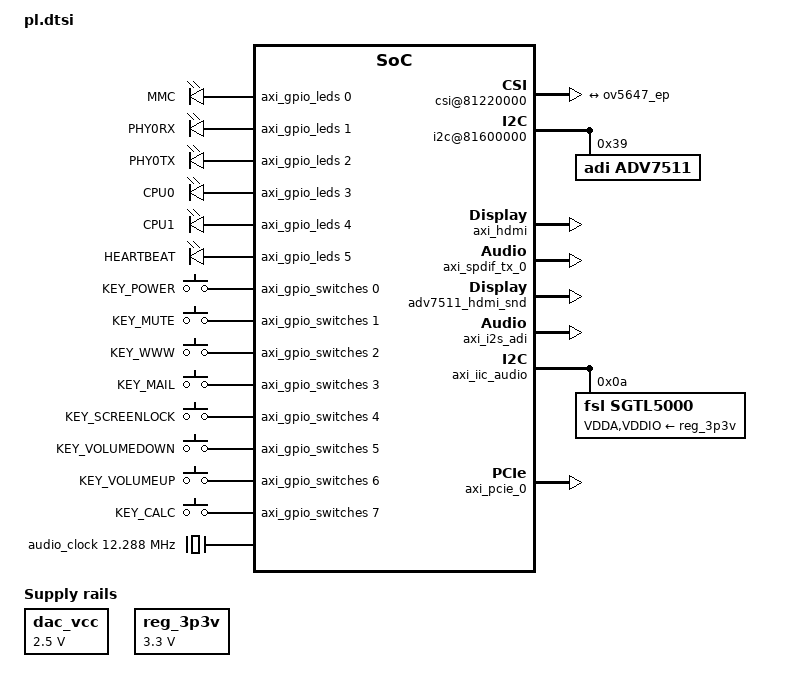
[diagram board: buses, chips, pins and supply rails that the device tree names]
/*
 * CAUTION: This file is automatically generated by Xilinx.
 * Version:  
 * Today is: Wed Jul 22 14:53:28 2015
*/


/ {

	dac_vcc: fixedregulator@1 {
		compatible = "regulator-fixed";
		regulator-name = "fixed-supply";
		regulator-min-microvolt = <2500000>;
		regulator-max-microvolt = <2500000>;
		regulator-boot-on;
	};

	amba_pl: amba_pl {
		#address-cells = <1>;
		#size-cells = <1>;
		compatible = "simple-bus";
		ranges;		
		
		axi_gpio_leds: gpio@81210000 {
			compatible = "xlnx,xps-gpio-1.00.a";
			reg = <0x81210000 0x10000>;
			
			interrupt-parent = <&intc>;
			interrupts = <0 33 4>;	
			
			gpio-controller;
			#gpio-cells = <2>;
			
			xlnx,all-inputs = <0x0>;
			xlnx,all-inputs-2 = <0x0>;
			xlnx,all-outputs = <0x1>;
			xlnx,all-outputs-2 = <0x0>;
			xlnx,dout-default = <0x00000000>;
			xlnx,dout-default-2 = <0x00000000>;
			xlnx,gpio-width = <0x9>;			
			xlnx,gpio2-width = <0x20>;
			xlnx,interrupt-present = <0x1>;
			xlnx,is-dual = <0x0>;
			xlnx,tri-default = <0xFFFFFFFF>;
			xlnx,tri-default-2 = <0xFFFFFFFF>;
		};
		
		axi_gpio_switches: gpio@81200000 {
			compatible = "xlnx,xps-gpio-1.00.a";
			reg = <0x81200000 0x10000>;
			
			interrupt-parent = <&intc>;
			interrupts = <0 34 4>;			
			
			gpio-controller;
			#gpio-cells = <2>;
			
			interrupt-controller;
			#interrupt-cells = <2>;
			
			xlnx,all-inputs = <0x1>;
			xlnx,all-inputs-2 = <0x0>;
			xlnx,all-outputs = <0x0>;
			xlnx,all-outputs-2 = <0x0>;
			xlnx,dout-default = <0x00000000>;
			xlnx,dout-default-2 = <0x00000000>;
			xlnx,gpio-width = <0x9>;
			xlnx,gpio2-width = <0x20>;
			xlnx,interrupt-present = <0x1>;
			xlnx,is-dual = <0x0>;
			xlnx,tri-default = <0xFFFFFFFF>;
			xlnx,tri-default-2 = <0xFFFFFFFF>;
		};		
		
		leds {
			compatible = "gpio-leds";
			
			led0 {
				label = "MMC";
				gpios = <&axi_gpio_leds 0 0>;
				linux,default-trigger = "mmc0";
			};

			led1 {
				label = "PHY0RX";
				gpios = <&axi_gpio_leds 1 0>;
				linux,default-trigger = "phy0rx";
			};

			led2 {
				label = "PHY0TX";
				gpios = <&axi_gpio_leds 2 0>;
				linux,default-trigger = "phy0tx";
			};
			
			led3 {
				label = "CPU0";
				gpios = <&axi_gpio_leds 3 0>;
				linux,default-trigger = "cpu0";
			};

			led4 {
				label = "CPU1";
				gpios = <&axi_gpio_leds 4 0>;
				linux,default-trigger = "cpu1";
			};
			
			led5 {
				label = "HEARTBEAT";
				gpios = <&axi_gpio_leds 5 0>;
				linux,default-trigger = "heartbeat";
			};						
		};
		
		gpio_keys_polled {
			compatible = "gpio-keys-polled";
			#address-cells = <1>;
			#size-cells = <0>;
			poll-interval = <100>;			
			
			switch0 {
				label = "KEY_POWER";
				linux,code = <116>;
				gpios = <&axi_gpio_switches 0 0>;
			};
			
			switch1 {
				label = "KEY_MUTE";
				linux,code = <113>;
				gpios = <&axi_gpio_switches 1 0>;
			};
			
			switch2 {
				label = "KEY_WWW";
				linux,code = <150>;
				gpios = <&axi_gpio_switches 2 0>;
			};
			
			switch3 {
				label = "KEY_MAIL";
				linux,code = <155>;
				gpios = <&axi_gpio_switches 3 0>;
			};
			
			switch4 {
				label = "KEY_SCREENLOCK";
				linux,code = <152>;
				gpios = <&axi_gpio_switches 4 0>;
			};
			
			switch5 {
				label = "KEY_VOLUMEDOWN";
				linux,code = <114>;
				gpios = <&axi_gpio_switches 5 0>;
			};
			
			switch6 {
				label = "KEY_VOLUMEUP";
				linux,code = <115>;
				gpios = <&axi_gpio_switches 6 0>;
			};
			
			switch7 {
				label = "KEY_CALC";
				linux,code = <140>;
				gpios = <&axi_gpio_switches 7 0>;
			};
		};				
		
		csi@81220000 {
			compatible = "s47,axi-csi-rx-1.00.a";
			reg = <0x81220000 0x10000>;

			interrupts = <0 53 4>;
			interrupt-parent = <&intc>;

			dmas = <&axi_camera_vdma 1>;
			dma-names = "video";

			led-gpios = <&axi_gpio_leds 7 0>;

			port {
				csi_ep: endpoint {
					remote-endpoint = <&ov5647_ep>;
					clock-lanes = <0>;
					data-lanes = <1 2>;
				};
			};
		};		
		
		axi_camera_vdma: dma@83010000 {		  
		  
			compatible = "xlnx,axi-vdma-1.00.a";
			#dma-cells = <1>;
			reg = <0x83010000 0x10000>;			
			
			/* Flush both channels on fsync */
			xlnx,flush-fsync = <0x1>;
			/* Number of framebuffers */
			xlnx,num-fstores = <0x4>;	
			
			/* Write channel: camera input */
			dma-channel@83010030 {
				compatible = "xlnx,axi-vdma-s2mm-channel";
				interrupt-parent = <&intc>;
				interrupts = <0 52 4>;
				xlnx,datawidth = <0x40>;
				xlnx,include-dre = <0x0>;				
				xlnx,genlock-mode = <0x0>;
			};
		};	
		
		i2c@81600000 {
			compatible = "xlnx,axi-iic-1.01.b", "xlnx,xps-iic-2.00.a";
			interrupt-parent = <&intc>;
			interrupts = <0 58 0x4>;
			reg = <0x81600000 0x10000>;

			#size-cells = <0>;
			#address-cells = <1>;

			adv7511: adv7511@39 {
				compatible = "adi,adv7511";
				reg = <0x39>;

				adi,input-style = <0x02>;
				adi,input-id = <0x01>;
				adi,input-color-depth = <0x3>;
				adi,sync-pulse = <0x03>;
				adi,bit-justification = <0x01>;
				adi,up-conversion = <0x00>;
				adi,timing-generation-sequence = <0x00>;
				adi,vsync-polarity = <0x02>;
				adi,hsync-polarity = <0x02>;
				adi,tdms-clock-inversion;
				adi,clock-delay = <0x03>;
			};			
		};

		axi_vdma_0: axivdma@83000000 {
			compatible = "xlnx,axi-vdma";
			#address-cells = <1>;
			#size-cells = <1>;
			#dma-cells = <1>;
			#dma-channels = <1>;
			reg = <0x83000000 0x10000>;
			xlnx,include-sg = <0x0>;
			xlnx,num-fstores = <0x3>;
			dma-channel@83000000 {
				compatible = "xlnx,axi-vdma-mm2s-channel";
				interrupt-parent = <&intc>;
				interrupts = <0 59 0x4>;
				xlnx,datawidth = <0x40>;
				xlnx,genlock-mode = <0x0>;
				xlnx,include-dre = <0x0>;
			};
		};

		hdmi_clock: axi-clkgen@83c00000 {
			compatible = "adi,axi-clkgen-2.00.a";
			reg = <0x83c00000 0x10000>;
			#clock-cells = <0>;
			clocks = <&clkc 16>;
		};

		axi_hdmi: axi-hdmi@83c10000 {
			compatible = "adi,axi-hdmi-tx-1.00.a";
			reg = <0x83c10000 0x10000>;
			encoder-slave = <&adv7511>;
			dmas = <&axi_vdma_0 0>;
			dma-names = "video";
			clocks = <&hdmi_clock>;
		};				

		axi_spdif_tx_0: axi-spdif-tx@0x83c20000 {
			compatible = "adi,axi-spdif-tx-1.00.a";
			reg = <0x83c20000 0x10000>;
			dmas = <&dmac_s 0>;
			dma-names = "tx";
			clocks = <&clkc 15>, <&audio_clock>, <&audio_clock>;
			clock-names = "axi", "ref", "spdif";
		};

		adv7511_hdmi_snd: adv7511_hdmi_snd {
			compatible = "adv7511-hdmi-snd";
			audio-codec = <&adv7511>;
			cpu-dai = <&axi_spdif_tx_0>;
		};			
		
		regulators {
			compatible = "simple-bus";			

			reg_3p3v: 3p3v {
				compatible = "regulator-fixed";
				regulator-name = "3P3V";
				regulator-min-microvolt = <3300000>;
				regulator-max-microvolt = <3300000>;
				regulator-always-on;
			};
		};		
		
		axi_i2s_adi: axi_i2s_adi@81640000 {
			#sound-dai-cells = <0>;
			compatible = "adi,axi-i2s-1.00.a";
			reg = <0x81640000 0x10000>;						
			dmas = <&dmac_s 1 &dmac_s 2>;
			dma-names = "tx", "rx";
			clocks = <&clkc 15>, <&audio_clock>;
			clock-names = "axi", "ref";						
		};
		
		axi_iic_audio: i2c@81610000 {
			#address-cells = <1>;
			#size-cells = <0>;
			compatible = "xlnx,axi-iic-1.01.b", "xlnx,xps-iic-2.00.a";
			interrupt-parent = <&intc>;
			interrupts = <0 56 4>;
			reg = <0x81610000 0x10000>;			
			
			sgtl5000: sgtl5000@0a {
				#sound-dai-cells = <0>;
				compatible = "fsl,sgtl5000";
				reg = <0x0a>;
				clocks = <&audio_clock>;								
				VDDA-supply = <&reg_3p3v>;
				VDDIO-supply = <&reg_3p3v>;				
			};			
		};
		
		upc_sgtl_sound {
		  
		    compatible = "simple-audio-card";
		    simple-audio-card,name = "Aldec-uPC-sound";
		    simple-audio-card,format = "i2s";
		    simple-audio-card,bitclock-master = <&dailink0_master>;
		    simple-audio-card,frame-master = <&dailink0_master>;
		    simple-audio-card,mclk-fs = <256>;
		    
		    simple-audio-card,widgets =
			    "Line", "Line In Jack",
			    "Headphone", "Headphone Jack";			    
		    simple-audio-card,routing =
			    "LINE_IN", "Line In Jack",
			    "Headphone Jack", "HP_OUT";		    
		    
		    dailink0_master: simple-audio-card,cpu {
			    sound-dai = <&axi_i2s_adi>;
			    system-clock-frequency = <12288000>;
		    };

		    simple-audio-card,codec {
			    sound-dai = <&sgtl5000>;
			    system-clock-frequency = <12288000>;
		    };		    
		};
		
		axi_pcie_0: axi-pcie@50000000 {
			#address-cells = <3>;
			#interrupt-cells = <1>;
			#size-cells = <2>;
			compatible = "xlnx,axi-pcie-host-1.00.a";
			device_type = "pci";
			interrupt-map = <0 0 0 1 &pcie_intc 1>,
					<0 0 0 2 &pcie_intc 2>,
					<0 0 0 3 &pcie_intc 3>, 
					<0 0 0 4 &pcie_intc 4>;
			interrupt-map-mask = <0 0 0 7>;
			interrupt-parent = <&intc>;
			interrupts = <0 57 4>;
			ranges = <0x02000000 0x00000000 0x60000000 0x60000000 0x00000000 0x10000000>;
			reg = <0x50000000 0x4000000>;
			pcie_intc: interrupt-controller {
				#address-cells = <0>;
				#interrupt-cells = <1>;
				interrupt-controller ;
			};
		};

		audio_clock: audio_clock {
			compatible = "fixed-clock";
			#clock-cells = <0>;
			clock-frequency = <12288000>;
		};				
	};
	
	
};
